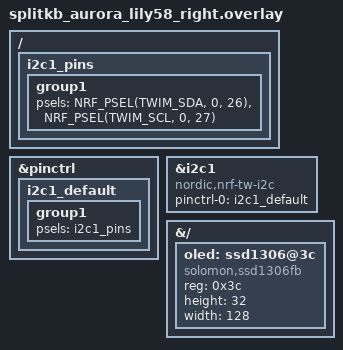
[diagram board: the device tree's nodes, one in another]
/ {
    i2c1_pins: i2c1_pins {
        group1 {
            psels = <NRF_PSEL(TWIM_SDA, 0, 26)>, <NRF_PSEL(TWIM_SCL, 0, 27)>;
        };
    };
};

&pinctrl {
    i2c1_default: i2c1_default {
        group1 {
            psels = <&i2c1_pins>;
        };
    };
};

&i2c1 {
    compatible = "nordic,nrf-tw-i2c";
    status = "okay";
    pinctrl-0 = <&i2c1_default>;
    pinctrl-names = "default";
};

oled: &{/} {
    oled: ssd1306@3c {
        compatible = "solomon,ssd1306fb";
        reg = <0x3c>;
        height = <32>;  /* Passe an dein OLED an */
        width = <128>;
        status = "okay";
    };
};
